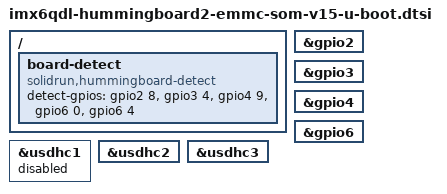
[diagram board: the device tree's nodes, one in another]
// SPDX-License-Identifier: GPL-2.0+

#include "imx6qdl-u-boot.dtsi"

/ {
	board-detect {
		compatible = "solidrun,hummingboard-detect";
		detect-gpios = <
			&gpio2 8 0
			&gpio3 4 0
			&gpio4 9 0
			&gpio6 0 0
			&gpio6 4 0
		>;
	};
};

&gpio2 {
	u-boot,dm-all;
};

&gpio3 {
	u-boot,dm-all;
};

&gpio4 {
	u-boot,dm-all;
};

&gpio6 {
	u-boot,dm-all;
};

&usdhc1 {
	status = "disabled";
};

&usdhc2 {
	u-boot,dm-all;
};

&usdhc3 {
	u-boot,dm-all;
};
